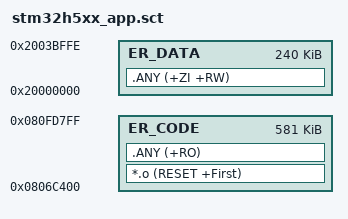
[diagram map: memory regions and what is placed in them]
#! armclang --target=arm-arm-none-eabi -march=armv8-m.main -E -xc

/*
 * Copyright (c) 2017-2018 ARM Limited
 *
 * Licensed under the Apache License, Version 2.0 (the "License");
 * you may not use this file except in compliance with the License.
 * You may obtain a copy of the License at
 *
 *     http://www.apache.org/licenses/LICENSE-2.0
 *
 * Unless required by applicable law or agreed to in writing, software
 * distributed under the License is distributed on an "AS IS" BASIS,
 * WITHOUT WARRANTIES OR CONDITIONS OF ANY KIND, either express or implied.
 * See the License for the specific language governing permissions and
 * limitations under the License.
 */

#define SECTOR_SIZE 0x2000            /* Size of a FLASH sector */
#define CODE_OFFSET 0x36*SECTOR_SIZE  /* This define is updated automatically by prebuild command */
#define CODE_SIZE 0x49*SECTOR_SIZE    /* This define is updated automatically by prebuild command */
#define IMAGE_HEADER_SIZE 0x400       /* mcuboot header size */
#define TRAILER_MAX_SIZE 0x800       /* max size TLV and trailer */
#define UNIT_SIZE 0x400               /* Size of a SRAM unit */
#define RAM_S_NS_IF_SIZE 0x10*UNIT_SIZE /* This define is updated automatically by prebuild command */
#define RAM_S_END 0x2006AFFF          /* This define is updated automatically by prebuild command */

#define CODE_START 0x08000000 + CODE_OFFSET + IMAGE_HEADER_SIZE
#define APP_CODE_SIZE CODE_SIZE - TRAILER_MAX_SIZE - IMAGE_HEADER_SIZE

#define DATA_START 0x20000000
#define DATA_SIZE 0x40000 - RAM_S_NS_IF_SIZE - 1
#define DATA_2_START RAM_S_END + 1
#define DATA_2_SIZE 0x2009FFFF - DATA_2_START + 1

LR_CODE CODE_START {
    ER_CODE CODE_START APP_CODE_SIZE {
        *.o (RESET +First)
        .ANY (+RO)
    }

    ER_DATA DATA_START DATA_SIZE {
        .ANY (+ZI +RW)
    }
}

